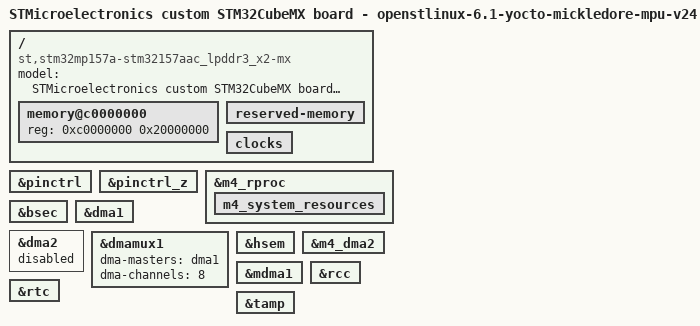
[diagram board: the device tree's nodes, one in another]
// SPDX-License-Identifier: (GPL-2.0-or-later OR BSD-3-Clause)
/*
 * Copyright (C) 2024, STMicroelectronics - All Rights Reserved
 * Author: STM32CubeMX code generation for STMicroelectronics.
 */

/* For more information on Device Tree configuration, please refer to
 * https://wiki.st.com/stm32mpu/wiki/Category:Device_tree_configuration
 */

/dts-v1/;

#include <dt-bindings/pinctrl/stm32-pinfunc.h>
#include "stm32mp157.dtsi"
#include "stm32mp15xa.dtsi"
#include "stm32mp15xxac-pinctrl.dtsi"
#include "stm32mp15-m4-srm.dtsi"

/* USER CODE BEGIN includes */
/* USER CODE END includes */

/ {
	model = "STMicroelectronics custom STM32CubeMX board - openstlinux-6.1-yocto-mickledore-mpu-v24.06.26";
	compatible = "st,stm32mp157a-stm32157aac_lpddr3_x2-mx", "st,stm32mp157";

	memory@c0000000 {
		device_type = "memory";
		reg = <0xc0000000 0x20000000>;

		/* USER CODE BEGIN memory */
		/* USER CODE END memory */
	};

	reserved-memory {
		#address-cells = <1>;
		#size-cells = <1>;
		ranges;

		/* USER CODE BEGIN reserved-memory */
		/* USER CODE END reserved-memory */
	};

	/* USER CODE BEGIN root */
	/* USER CODE END root */

	clocks{

		/* USER CODE BEGIN clocks */
		/* USER CODE END clocks */
	};

}; /*root*/

&pinctrl {

	/* USER CODE BEGIN pinctrl */
	/* USER CODE END pinctrl */
};

&pinctrl_z {

	/* USER CODE BEGIN pinctrl_z */
	/* USER CODE END pinctrl_z */
};

&m4_rproc{
	status = "okay";

	/* USER CODE BEGIN m4_rproc */
	/* USER CODE END m4_rproc */

	m4_system_resources{
		status = "okay";

		/* USER CODE BEGIN m4_system_resources */
		/* USER CODE END m4_system_resources */
	};
};

&bsec{
	status = "okay";

	/* USER CODE BEGIN bsec */
	/* USER CODE END bsec */
};

&dma1{
	status = "okay";

	/* USER CODE BEGIN dma1 */
	/* USER CODE END dma1 */
};

&dma2{
	status = "disabled";

	/* USER CODE BEGIN dma2 */
	/* USER CODE END dma2 */
};

&dmamux1{
	status = "okay";

	dma-masters = <&dma1>;
	dma-channels = <8>;

	/* USER CODE BEGIN dmamux1 */
	/* USER CODE END dmamux1 */
};

&hsem{
	status = "okay";

	/* USER CODE BEGIN hsem */
	/* USER CODE END hsem */
};

&m4_dma2{
	status = "okay";

	/* USER CODE BEGIN m4_dma2 */
	/* USER CODE END m4_dma2 */
};

&mdma1{
	status = "okay";

	/* USER CODE BEGIN mdma1 */
	/* USER CODE END mdma1 */
};

&rcc{
	status = "okay";

	/* USER CODE BEGIN rcc */
	/* USER CODE END rcc */
};

&rtc{
	status = "okay";

	/* USER CODE BEGIN rtc */
	/* USER CODE END rtc */
};

&tamp{
	status = "okay";

	/* USER CODE BEGIN tamp */
	/* USER CODE END tamp */
};

/* USER CODE BEGIN addons */
/* USER CODE END addons */

